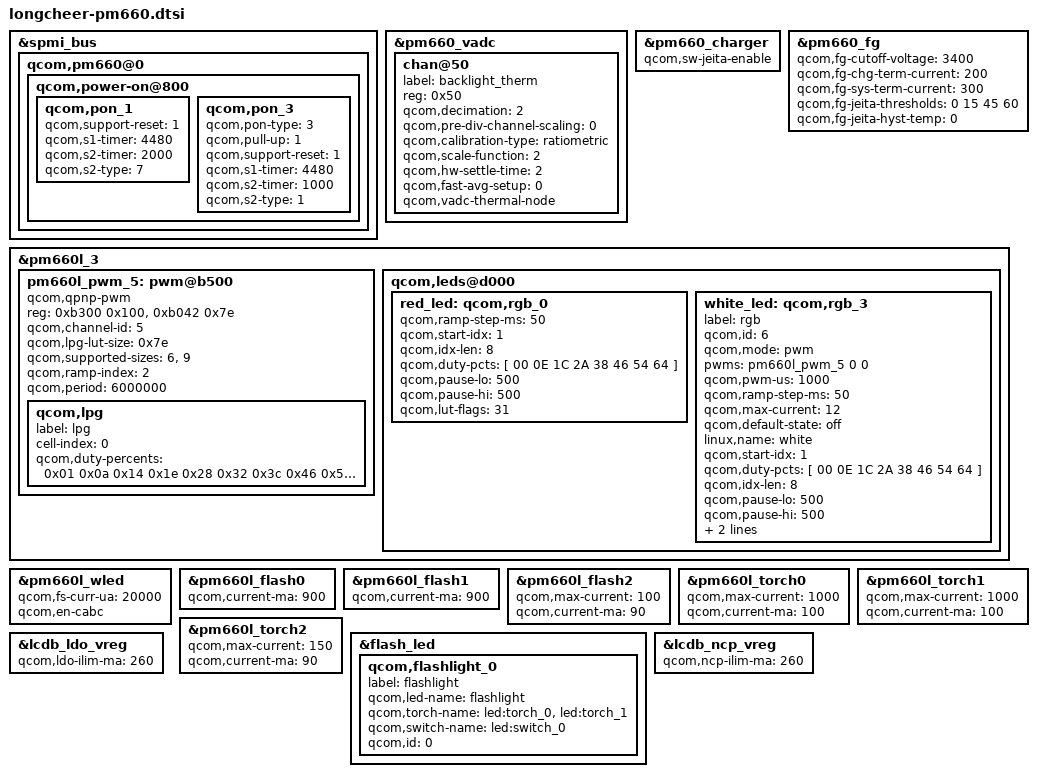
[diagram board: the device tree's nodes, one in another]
/* Copyright (c) 2019, The Linux Foundation. All rights reserved.
 *
 * This program is free software; you can redistribute it and/or modify
 * it under the terms of the GNU General Public License version 2 and
 * only version 2 as published by the Free Software Foundation.
 *
 * This program is distributed in the hope that it will be useful,
 * but WITHOUT ANY WARRANTY; without even the implied warranty of
 * MERCHANTABILITY or FITNESS FOR A PARTICULAR PURPOSE.  See the
 * GNU General Public License for more details.
 */

/* common diff with msm-pm660.dtsi */
&spmi_bus {
	qcom,pm660@0 {
		qcom,power-on@800 {
			qcom,pon_1 {
				qcom,support-reset = <1>;
				qcom,s1-timer = <4480>;
				qcom,s2-timer = <2000>;
				qcom,s2-type = <7>;
			};

			qcom,pon_3 {
				qcom,pon-type = <3>;
				qcom,pull-up = <1>;
				qcom,support-reset = <1>;
				qcom,s1-timer = <4480>;
				qcom,s2-timer = <1000>;
				qcom,s2-type = <1>;
			};
		};
	};
};

&pm660_vadc {
	chan@50 {
		label = "backlight_therm";
		reg = <0x50>;
		qcom,decimation = <2>;
		qcom,pre-div-channel-scaling = <0>;
		qcom,calibration-type = "ratiometric";
		qcom,scale-function = <2>;
		qcom,hw-settle-time = <2>;
		qcom,fast-avg-setup = <0>;
		qcom,vadc-thermal-node;
	};
};

&pm660_charger {
	qcom,sw-jeita-enable;
};

&pm660_fg {
	qcom,fg-cutoff-voltage = <3400>;
	qcom,fg-chg-term-current = <200>;
	qcom,fg-sys-term-current = <300>;
	qcom,fg-jeita-thresholds = <0 15 45 60>;
	qcom,fg-jeita-hyst-temp = <0>;
};

/* common diff with msm-pm660l.dtsi */
&pm660l_3 {
	pm660l_pwm_5: pwm@b500 {
		compatible = "qcom,qpnp-pwm";
		reg = <0xb300 0x100>,
		      <0xb042 0x7e>;
		reg-names = "qpnp-lpg-channel-base",
				 "qpnp-lpg-lut-base";
		qcom,channel-id = <5>;
		qcom,lpg-lut-size = <0x7e>;
		qcom,supported-sizes = <6>, <9>;
		qcom,ramp-index = <2>;
		#pwm-cells = <2>;
		qcom,period = <6000000>;

		qcom,lpg {
			label = "lpg";
			cell-index = <0>;
			qcom,duty-percents =
				<0x01 0x0a 0x14 0x1e 0x28 0x32 0x3c
				0x46 0x50 0x5a 0x64
				0x64 0x5a 0x50 0x46 0x3c 0x32 0x28 0x1e
				0x14 0x0a 0x01>;
		};
	};

	qcom,leds@d000 {
		red_led: qcom,rgb_0 {
			qcom,ramp-step-ms = <50>;
			qcom,start-idx = <1>;
			qcom,idx-len = <8>;
			qcom,duty-pcts = [ 00 0E 1C 2A 38 46 54 64 ];
			qcom,pause-lo = <500>;
			qcom,pause-hi = <500>;
			qcom,lut-flags = <31>; /* loop, ramp up, reverse, pause hi, pause lo */
		};

		white_led: qcom,rgb_3 {
			label = "rgb";
			qcom,id = <6>;
			qcom,mode = "pwm";
			pwms = <&pm660l_pwm_5 0 0>;
			qcom,pwm-us = <1000>;
			qcom,ramp-step-ms = <50>;
			qcom,max-current = <12>;
			qcom,default-state = "off";
			linux,name = "white";
			qcom,start-idx = <1>;
			qcom,duty-pcts = [ 00 0E 1C 2A 38 46 54 64 ];
			qcom,idx-len = <8>;
			qcom,pause-lo = <500>;
			qcom,pause-hi = <500>;
			qcom,lut-flags = <31>; /* loop, ramp up, reverse, pause hi, pause lo */
			qcom,use-blink;
		};
	};
};

&pm660l_wled {
	/delete-property/ qcom,auto-calibration-enable;
	qcom,fs-curr-ua = <20000>;
	qcom,en-cabc;
};

&pm660l_flash0 {
	qcom,current-ma = <900>;
};

&pm660l_flash1{
	qcom,current-ma = <900>;
};

&pm660l_flash2 {
	qcom,max-current = <100>;
	qcom,current-ma = <90>;
};

&pm660l_torch0 {
	qcom,max-current = <1000>;
	qcom,current-ma = <100>;
};

&pm660l_torch1 {
	qcom,max-current = <1000>;
	qcom,current-ma = <100>;
};

&pm660l_torch2 {
	qcom,max-current = <150>;
	qcom,current-ma = <90>;
};

&flash_led {
	qcom,flashlight_0 {
		label = "flashlight";
		qcom,led-name = "flashlight";
		qcom,torch-name = "led:torch_0", "led:torch_1";
		qcom,switch-name = "led:switch_0";
		qcom,id = <0>;
	};
};

&lcdb_ldo_vreg {
	qcom,ldo-ilim-ma = <260>;
};

&lcdb_ncp_vreg {
	qcom,ncp-ilim-ma = <260>;
};
